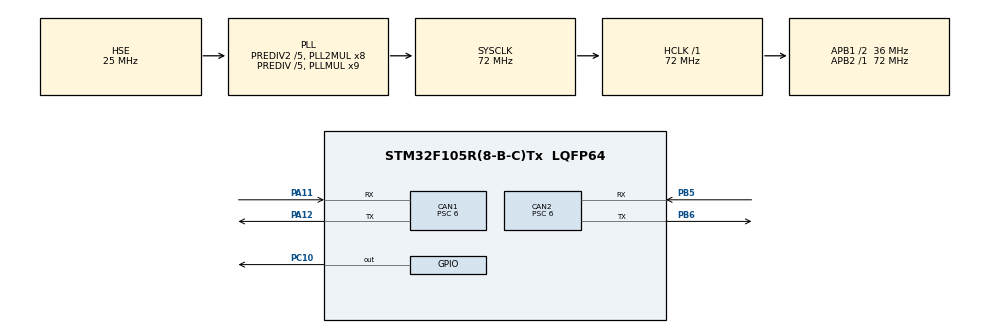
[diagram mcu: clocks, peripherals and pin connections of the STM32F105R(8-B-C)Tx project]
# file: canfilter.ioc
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CAN1.BS1=CAN_BS1_8TQ
CAN1.BS2=CAN_BS2_3TQ
CAN1.CalculateBaudRate=499999
CAN1.CalculateTimeBit=2000
CAN1.CalculateTimeQuantum=166.66666666666669
CAN1.Prescaler=6
CAN2.BS1=CAN_BS1_8TQ
CAN2.BS2=CAN_BS2_3TQ
CAN2.CalculateBaudRate=499999
CAN2.CalculateTimeBit=2000
CAN2.CalculateTimeQuantum=166.66666666666669
CAN2.Prescaler=6
Mcu.Family=STM32F1
Mcu.Name=STM32F105R(8-B-C)Tx
Mcu.Package=LQFP64
NVIC.PriorityGroup=NVIC_PRIORITYGROUP_0
PA11.Mode=CAN_Activate
PA11.Signal=CAN1_RX
PA12.Mode=CAN_Activate
PA12.Signal=CAN1_TX
PA13.Mode=Serial_Wire
PA13.Signal=SYS_JTMS-SWDIO
PA14.Mode=Serial_Wire
PA14.Signal=SYS_JTCK-SWCLK
PB5.Mode=CAN_Activate
PB5.Signal=CAN2_RX
PB6.Mode=CAN_Activate
PB6.Signal=CAN2_TX
PC10.PinState=GPIO_PIN_SET
PC10.Signal=GPIO_Output
PD0-OSC_IN.Mode=HSE-External-Oscillator
PD0-OSC_IN.Signal=RCC_OSC_IN
PD1-OSC_OUT.Mode=HSE-External-Oscillator
PD1-OSC_OUT.Signal=RCC_OSC_OUT
ProjectManager.HeapSize=0x200
ProjectManager.StackSize=0x400
ProjectManager.TargetToolchain=STM32CubeIDE
RCC.AHBFreq_Value=72000000
RCC.APB1CLKDivider=RCC_HCLK_DIV2
RCC.APB1Freq_Value=36000000
RCC.APB1TimFreq_Value=72000000
RCC.APB2Freq_Value=72000000
RCC.APB2TimFreq_Value=72000000
RCC.HCLKFreq_Value=72000000
RCC.HSEDivPLL=RCC_HSE_PREDIV_DIV5
RCC.HSE_VALUE=25000000
RCC.PLLMUL=RCC_PLL_MUL9
RCC.PLLSourceVirtual=RCC_PLLSOURCE_HSE
RCC.Prediv1Source=RCC_PREDIV1_SOURCE_PLL2
RCC.Prediv2=RCC_HSE_PREDIV2_DIV5
RCC.SYSCLKFreq_VALUE=72000000
RCC.SYSCLKSource=RCC_SYSCLKSOURCE_PLLCLK
RCC.USBFreq_Value=48000000
board=custom

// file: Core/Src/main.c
/* USER CODE BEGIN Header */
/**
 ******************************************************************************
 * @file           : main.c
 * @brief          : Main program body
 ******************************************************************************
 * @attention
 *
 * <h2><center>&copy; Copyright (c) 2020 STMicroelectronics.
 * All rights reserved.</center></h2>
 *
 * This software component is licensed by ST under BSD 3-Clause license,
 * the "License"; You may not use this file except in compliance with the
 * License. You may obtain a copy of the License at:
 *                        opensource.org/licenses/BSD-3-Clause
 *
 ******************************************************************************
 */
/* USER CODE END Header */

#include "main.h"

/* USER CODE BEGIN Includes */
#include <string.h>
#include "canfilter.h"
/* USER CODE END Includes */

CAN_HandleTypeDef hcan1;
CAN_HandleTypeDef hcan2;

void SystemClock_Config(void);
static void MX_GPIO_Init(void);
static void MX_CAN1_Init(void);
static void MX_CAN2_Init(void);

int main(void) {

	/* MCU Configuration--------------------------------------------------------*/

	/* Reset of all peripherals, Initializes the Flash interface and the Systick. */
	HAL_Init();

	/* Configure the system clock */
	SystemClock_Config();

	/* Initialize all configured peripherals */
	MX_GPIO_Init();
	MX_CAN1_Init();
	MX_CAN2_Init();
	/* USER CODE BEGIN 2 */
	canloop(&hcan1, &hcan2);

	/* USER CODE END 2 */

	/* USER CODE END 3 */
}

void SystemClock_Config(void) {
	RCC_OscInitTypeDef RCC_OscInitStruct = { 0 };
	RCC_ClkInitTypeDef RCC_ClkInitStruct = { 0 };

	/** Initializes the CPU, AHB and APB busses clocks
	 */
	RCC_OscInitStruct.OscillatorType = RCC_OSCILLATORTYPE_HSE;
	RCC_OscInitStruct.HSEState = RCC_HSE_ON;
	RCC_OscInitStruct.HSEPredivValue = RCC_HSE_PREDIV_DIV5;
	RCC_OscInitStruct.HSIState = RCC_HSI_ON;
	RCC_OscInitStruct.Prediv1Source = RCC_PREDIV1_SOURCE_PLL2;
	RCC_OscInitStruct.PLL.PLLState = RCC_PLL_ON;
	RCC_OscInitStruct.PLL.PLLSource = RCC_PLLSOURCE_HSE;
	RCC_OscInitStruct.PLL.PLLMUL = RCC_PLL_MUL9;
	RCC_OscInitStruct.PLL2.PLL2State = RCC_PLL2_ON;
	RCC_OscInitStruct.PLL2.PLL2MUL = RCC_PLL2_MUL8;
	RCC_OscInitStruct.PLL2.HSEPrediv2Value = RCC_HSE_PREDIV2_DIV5;
	if (HAL_RCC_OscConfig(&RCC_OscInitStruct) != HAL_OK) {
		Error_Handler();
	}
	/** Initializes the CPU, AHB and APB busses clocks
	 */
	RCC_ClkInitStruct.ClockType = RCC_CLOCKTYPE_HCLK | RCC_CLOCKTYPE_SYSCLK
			| RCC_CLOCKTYPE_PCLK1 | RCC_CLOCKTYPE_PCLK2;
	RCC_ClkInitStruct.SYSCLKSource = RCC_SYSCLKSOURCE_PLLCLK;
	RCC_ClkInitStruct.AHBCLKDivider = RCC_SYSCLK_DIV1;
	RCC_ClkInitStruct.APB1CLKDivider = RCC_HCLK_DIV2;
	RCC_ClkInitStruct.APB2CLKDivider = RCC_HCLK_DIV1;

	if (HAL_RCC_ClockConfig(&RCC_ClkInitStruct, FLASH_LATENCY_2) != HAL_OK) {
		Error_Handler();
	}
	/** Configure the Systick interrupt time
	 */
	__HAL_RCC_PLLI2S_ENABLE();
}

static void MX_CAN1_Init(void) {

	/* USER CODE BEGIN CAN1_Init 0 */
// Konfig taken from: https://www.elektronik-keller.de/index.php/projekte/stm32/29-stm32cubemx-stm32-can
	/* USER CODE END CAN1_Init 0 */

	/* USER CODE BEGIN CAN1_Init 1 */
	CAN_FilterTypeDef sFilterConfig;
	/* USER CODE END CAN1_Init 1 */
	hcan1.Instance = CAN1;
	hcan1.Init.Prescaler = 6;
	hcan1.Init.Mode = CAN_MODE_NORMAL;
	hcan1.Init.SyncJumpWidth = CAN_SJW_1TQ;
	hcan1.Init.TimeSeg1 = CAN_BS1_8TQ;
	hcan1.Init.TimeSeg2 = CAN_BS2_3TQ;
	hcan1.Init.TimeTriggeredMode = DISABLE;
	hcan1.Init.AutoBusOff = DISABLE;
	hcan1.Init.AutoWakeUp = DISABLE;
	hcan1.Init.AutoRetransmission = DISABLE;
	hcan1.Init.ReceiveFifoLocked = DISABLE;
	hcan1.Init.TransmitFifoPriority = DISABLE;
	if (HAL_CAN_Init(&hcan1) != HAL_OK) {
		Error_Handler();
	}
	/* USER CODE BEGIN CAN1_Init 2 */

	/*##-2- Configure the CAN Filter ###########################################*/

	sFilterConfig.FilterBank = 0;
	sFilterConfig.FilterMode = CAN_FILTERMODE_IDMASK;
	sFilterConfig.FilterScale = CAN_FILTERSCALE_32BIT;
	sFilterConfig.FilterIdHigh = 0x0000;
	sFilterConfig.FilterIdLow = 0x0000;
	sFilterConfig.FilterMaskIdHigh = 0x0000;
	sFilterConfig.FilterMaskIdLow = 0x0000;
	sFilterConfig.FilterFIFOAssignment = CAN_RX_FIFO0;
	sFilterConfig.FilterActivation = ENABLE;
	sFilterConfig.SlaveStartFilterBank = 14;

	if (HAL_CAN_ConfigFilter(&hcan1, &sFilterConfig) != HAL_OK) {
		/* Filter configuration Error */
		Error_Handler();
	}
	/*##-3- Start the CAN peripheral ###########################################*/
	if (HAL_CAN_Start(&hcan1) != HAL_OK) {
		/* Start Error */
		Error_Handler();
	}

}

static void MX_CAN2_Init(void) {

	/* USER CODE BEGIN CAN2_Init 0 */
	CAN_FilterTypeDef sFilterConfig;
	/* USER CODE END CAN2_Init 0 */

	hcan2.Instance = CAN2;
	hcan2.Init.Prescaler = 6;
	hcan2.Init.Mode = CAN_MODE_NORMAL;
	hcan2.Init.SyncJumpWidth = CAN_SJW_1TQ;
	hcan2.Init.TimeSeg1 = CAN_BS1_8TQ;
	hcan2.Init.TimeSeg2 = CAN_BS2_3TQ;
	hcan2.Init.TimeTriggeredMode = DISABLE;
	hcan2.Init.AutoBusOff = DISABLE;
	hcan2.Init.AutoWakeUp = DISABLE;
	hcan2.Init.AutoRetransmission = DISABLE;
	hcan2.Init.ReceiveFifoLocked = DISABLE;
	hcan2.Init.TransmitFifoPriority = DISABLE;
	if (HAL_CAN_Init(&hcan2) != HAL_OK) {
		Error_Handler();
	}

	sFilterConfig.FilterBank = 15;
	sFilterConfig.FilterMode = CAN_FILTERMODE_IDMASK;
	sFilterConfig.FilterScale = CAN_FILTERSCALE_32BIT;
	sFilterConfig.FilterIdHigh = 0x0000;
	sFilterConfig.FilterIdLow = 0x0000;
	sFilterConfig.FilterMaskIdHigh = 0x0000;
	sFilterConfig.FilterMaskIdLow = 0x0000;
	sFilterConfig.FilterFIFOAssignment = CAN_RX_FIFO1;
	sFilterConfig.FilterActivation = ENABLE;
	sFilterConfig.SlaveStartFilterBank = 15;

	if (HAL_CAN_ConfigFilter(&hcan2, &sFilterConfig) != HAL_OK) {
		/* Filter configuration Error */
		Error_Handler();
	}
	/* USER CODE BEGIN CAN2_Init 2 */
	if (HAL_CAN_Start(&hcan2) != HAL_OK) {
		/* Start Error */
		Error_Handler();
	}
	/* USER CODE END CAN2_Init 2 */

}

static void MX_GPIO_Init(void) {
	GPIO_InitTypeDef GPIO_InitStruct = { 0 };

	/* GPIO Ports Clock Enable */
	__HAL_RCC_GPIOD_CLK_ENABLE();
	__HAL_RCC_GPIOA_CLK_ENABLE();
	__HAL_RCC_GPIOC_CLK_ENABLE();
	__HAL_RCC_GPIOB_CLK_ENABLE();

	/*Configure GPIO pin Output Level */
	HAL_GPIO_WritePin(GPIOC, GPIO_PIN_10, GPIO_PIN_SET);

	/*Configure GPIO pin : PC10 */
	GPIO_InitStruct.Pin = GPIO_PIN_10;
	GPIO_InitStruct.Mode = GPIO_MODE_OUTPUT_PP;
	GPIO_InitStruct.Pull = GPIO_NOPULL;
	GPIO_InitStruct.Speed = GPIO_SPEED_FREQ_LOW;
	HAL_GPIO_Init(GPIOC, &GPIO_InitStruct);

}

void Error_Handler(void) {
	/* USER CODE BEGIN Error_Handler_Debug */
	/* User can add his own implementation to report the HAL error return state */

	/* Infinite loop */
	/* USER CODE BEGIN WHILE */

	//while (1) {
	/* USER CODE END WHILE */

	//HAL_GPIO_TogglePin(GPIOC, GPIO_PIN_10);
	//HAL_Delay(300);
	/* USER CODE BEGIN 3 */
	//}
	/* USER CODE END Error_Handler_Debug */
}

/************************ (C) COPYRIGHT STMicroelectronics *****END OF FILE****/
